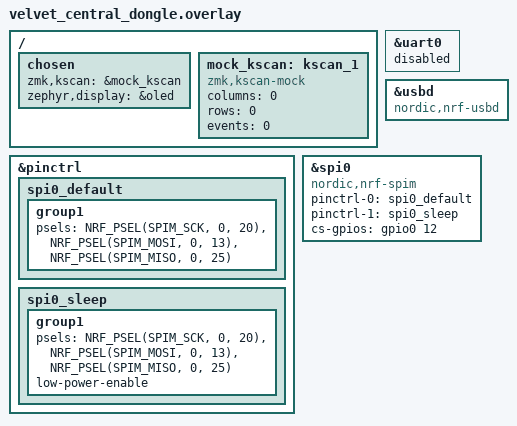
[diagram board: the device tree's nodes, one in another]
/*
 * Copyright (c) 2020 The ZMK Contributors
 *
 * SPDX-License-Identifier: MIT
 */
#include <zephyr/dt-bindings/input/input-event-codes.h>
#include <input/processors.dtsi>
#include <dt-bindings/zmk/input_transform.h>
#include "velvet.dtsi"

/ {
    chosen {
        zmk,kscan = &mock_kscan;
        zephyr,display = &oled;
    };
    mock_kscan: kscan_1 {
        compatible = "zmk,kscan-mock";
        columns = <0>;
        rows = <0>;
        events = <0>;
    };
};

&uart0 {
	status = "disabled";
};

zephyr_udc0: &usbd {
    compatible = "nordic,nrf-usbd";
    status = "okay";
};

&pinctrl {

    spi0_default: spi0_default {
        group1 {
            psels = <NRF_PSEL(SPIM_SCK, 0, 20)>,
                <NRF_PSEL(SPIM_MOSI, 0, 13)>,
                <NRF_PSEL(SPIM_MISO, 0, 25)>;
        };
    };

    spi0_sleep: spi0_sleep {
        group1 {
            psels = <NRF_PSEL(SPIM_SCK, 0, 20)>,
                <NRF_PSEL(SPIM_MOSI, 0, 13)>,
                <NRF_PSEL(SPIM_MISO, 0, 25)>;
            low-power-enable;
        };
    };
};

nice_view_spi: &spi0 {
    compatible = "nordic,nrf-spim";
    pinctrl-0 = <&spi0_default>;
    pinctrl-1 = <&spi0_sleep>;
    pinctrl-names = "default", "sleep";
    cs-gpios = <&gpio0 12 GPIO_ACTIVE_HIGH>;
};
